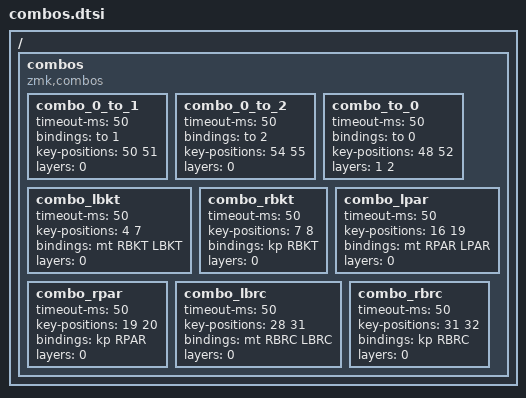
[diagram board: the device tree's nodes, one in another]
/ {
    combos {
        compatible = "zmk,combos";

        combo_0_to_1 {
            timeout-ms = <50>;
            bindings = <&to 1>;
            key-positions = <50 51>;
            layers = <0>;
	   };

        combo_0_to_2 {
            timeout-ms = <50>;
            bindings = <&to 2>;
            key-positions = <54 55>;
            layers = <0>;
	   };

        combo_to_0 {
            timeout-ms = <50>;
            bindings = <&to 0>;
            key-positions = <48 52>;
            layers = <1 2>;
	};

	combo_lbkt {
	    timeout-ms = <50>;
	    key-positions = <4 7>; // KP: RT
	    bindings = <&mt RBKT LBKT>; // ][ // 可以用CMD+这个单手返回到代码上一个编辑的地方 或者网页返回
	    layers = <0>;
	};

	combo_rbkt {
	    timeout-ms = <50>;
	    key-positions = <7 8>; // KP: YU
	    bindings = <&kp RBKT>; // ]
	    layers = <0>;
	};

	combo_lpar {
	    timeout-ms = <50>;
	    key-positions = <16 19>; // KP: FG
	    bindings = <&mt RPAR LPAR>; // )(
	    layers = <0>;
	};

	combo_rpar {
	    timeout-ms = <50>;
	    key-positions = <19 20>; // KP: HJ
	    bindings = <&kp RPAR>; // )
	    layers = <0>;
	};

	combo_lbrc {
	    timeout-ms = <50>;
	    key-positions = <28 31>; // KP: VB
	    bindings = <&mt RBRC LBRC>; // }{
	    layers = <0>;
	};

	combo_rbrc {
	    timeout-ms = <50>;
	    key-positions = <31 32>; // KP: NM
	    bindings = <&kp RBRC>; // }
	    layers = <0>;
	}; 

	//combo_bt_sel {
        //    bindings = <&mo 5>;
        //    key-positions = <48 52>;
        //    layers = <0>;
	//};

        //CapsWord {
        //    bindings = <&caps_word>;
        //    key-positions = <17 18>;
        //    layers = <0>;
        //};

        //combo_BASE_or_EXTRAS {
        //    bindings = <&td_bore>;
        //    key-positions = <38 39>;
        //};
        //
        //combo_left_click {
        //    bindings = <&mkp LCLK>;
        //    key-positions = <25 26>;
        //};
        //
        //combo_middle_click {
        //    bindings = <&mkp MCLK>;
        //    key-positions = <26 27>;
        //};

        //combo_right_click {
        //    bindings = <&mkp RCLK>;
        //    key-positions = <27 28>;
        //};
    };
};
